# ATtiny202 register map
Vendor: Atmel; File version: 1.0
CPU: other r0p0, little endian, no MPU, no FPU, 4 interrupt priority bits
Registers are 8-bit, read-write, reset 0x0 unless marked. A register's access mark holds for its fields unless they carry their own. Offsets are from the block's base; [hi:lo] are bit positions; {n}, {i} and the like mark numbered series; 'fields as' and 'values as' point back to an identical list.

## CPU
Base 0x00800034
0x00 CCP — Configuration Change Protection
  [7:0] CCP — CCP signature
    157=SPM (SPM Instruction Protection); 216=IOREG (IO Register Protection)
0x09 SPL — Stack Pointer Low
0x0A SPH — Stack Pointer High
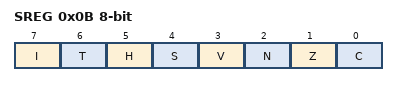
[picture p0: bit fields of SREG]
0x0B SREG — Status Register
  [7] I — Global Interrupt Enable Flag
  [6] T — Transfer Bit
  [5] H — Half Carry Flag
  [4] S — N Exclusive Or V Flag
  [3] V — Two's Complement Overflow Flag
  [2] N — Negative Flag
  [1] Z — Zero Flag
  [0] C — Carry Flag

## CPUINT — Interrupt Controller
Base 0x00800110
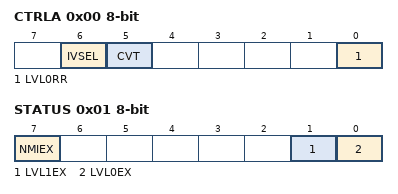
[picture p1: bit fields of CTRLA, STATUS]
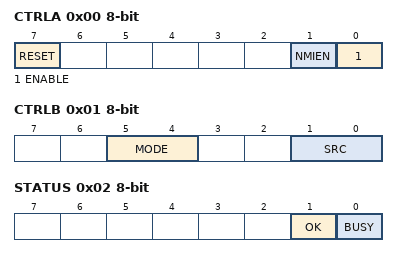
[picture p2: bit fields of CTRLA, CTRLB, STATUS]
0x00 CTRLA — Control A
  [6] IVSEL — Interrupt Vector Select
  [5] CVT — Compact Vector Table
  [0] LVL0RR — Round-robin Scheduling Enable
0x01 STATUS
  [7] NMIEX ro — Non-maskable Interrupt Executing
  [1] LVL1EX ro — Level 1 Interrupt Executing
  [0] LVL0EX ro — Level 0 Interrupt Executing
0x02 LVL0PRI — Interrupt Level 0 Priority
  [7:0] LVL0PRI — Interrupt Level Priority
0x03 LVL1VEC — Interrupt Level 1 Priority Vector
  [7:0] LVL1VEC — Interrupt Vector with High Priority

## CRCSCAN
Base 0x00800120
0x00 CTRLA — Control A
  [7] RESET — Reset CRC scan
  [1] NMIEN — Enable NMI Trigger
  [0] ENABLE — Enable CRC scan
0x01 CTRLB — Control B
  [5:4] MODE — CRC Flash Access Mode
    0=PRIORITY (Priority to flash)
  [1:0] SRC — CRC Source
    0=FLASH (CRC on entire flash); 1=APPLICATION (CRC on boot and appl section of flash); 2=BOOT (CRC on boot section of flash)
0x02 STATUS ro
  [1] OK — CRC Ok
  [0] BUSY — CRC Busy

## EVSYS — Event System
Base 0x00800180
0x00 ASYNCSTROBE wo — Asynchronous Channel Strobe
0x01 SYNCSTROBE wo — Synchronous Channel Strobe
0x02 ASYNCCH0 — Asynchronous Channel 0 Generator Selection
  [7:0] ASYNCCH0
    0=OFF; 1=CCL_LUT0 (Configurable Custom Logic LUT0); 2=CCL_LUT1 (Configurable Custom Logic LUT1); 3=AC0_OUT (Analog Comparator 0 out); 4=TCD0_CMPBCLR (Timer/Counter D0 compare B clear); 5=TCD0_CMPASET (Timer/Counter D0 compare A set); 6=TCD0_CMPBSET (Timer/Counter D0 compare B set); 7=TCD0_PROGEV (Timer/Counter D0 program event); 8=RTC_OVF (Real Time Counter overflow); 9=RTC_CMP (Real Time Counter compare); {v}=PORTA_PIN{v-10} (Asynchronous Event from Pin PA{v-10}) (v=10..17); 18=UPDI (Unified Program and debug interface)
0x03 ASYNCCH1 — Asynchronous Channel 1 Generator Selection
  [7:0] ASYNCCH1
    0=OFF; 1=CCL_LUT0 (Configurable custom logic LUT0); 2=CCL_LUT1 (Configurable custom logic LUT1); 3=AC0_OUT (Analog Comparator 0 out); 4=TCD0_CMPBCLR (Timer/Counter D0 compare B clear); 5=TCD0_CMPASET (Timer/Counter D0 compare A set); 6=TCD0_CMPBSET (Timer/Counter D0 compare B set); 7=TCD0_PROGEV (Timer/Counter D0 program event); 8=RTC_OVF (Real Time Counter overflow); 9=RTC_CMP (Real Time Counter compare); {v}=PORTB_PIN{v-10} (Asynchronous Event from Pin PB{v-10}) (v=10..17)
0x0A SYNCCH0 — Synchronous Channel 0 Generator Selection
  [7:0] SYNCCH0
    0=OFF; 1=TCB0 (Timer/Counter B0); 2=TCA0_OVF_LUNF (Timer/Counter A0 overflow); 3=TCA0_HUNF (Timer/Counter A0 underflow high byte (split mode)); 4=TCA0_CMP0 (Timer/Counter A0 compare 0); 5=TCA0_CMP1 (Timer/Counter A0 compare 1); 6=TCA0_CMP2 (Timer/Counter A0 compare 2); {v}=PORTC_PIN{v-7} (Synchronous Event from Pin PC{v-7}) (v=7..12); {v}=PORTA_PIN{v-13} (Synchronous Event from Pin PA{v-13}) (v=13..20)
0x0B SYNCCH1 — Synchronous Channel 1 Generator Selection
  [7:0] SYNCCH1
    0=OFF; 1=TCB0 (Timer/Counter B0); 2=TCA0_OVF_LUNF (Timer/Counter A0 overflow); 3=TCA0_HUNF (Timer/Counter A0 underflow high byte (split mode)); 4=TCA0_CMP0 (Timer/Counter A0 compare 0); 5=TCA0_CMP1 (Timer/Counter A0 compare 1); 6=TCA0_CMP2 (Timer/Counter A0 compare 2); {v}=PORTB_PIN{v-8} (Synchronous Event from Pin PB{v-8}) (v=8..15)
0x12 ASYNCUSER0 — Asynchronous User Ch 0 Input Selection - TCB0
  [7:0] ASYNCUSER0
    0=OFF; 1=SYNCCH0 (Synchronous Event Channel 0); 3=ASYNCCH0 (Asynchronous Event Channel 0); 4=ASYNCCH1 (Asynchronous Event Channel 1)
0x13 ASYNCUSER1 — Asynchronous User Ch 1 Input Selection - ADC0
  [7:0] ASYNCUSER1
    values as ASYNCUSER0.ASYNCUSER0
0x14 ASYNCUSER2 — Asynchronous User Ch 2 Input Selection - CCL LUT0 Event 0
  [7:0] ASYNCUSER2
    values as ASYNCUSER0.ASYNCUSER0
0x15 ASYNCUSER3 — Asynchronous User Ch 3 Input Selection - CCL LUT1 Event 0
  [7:0] ASYNCUSER3
    values as ASYNCUSER0.ASYNCUSER0
0x16 ASYNCUSER4 — Asynchronous User Ch 4 Input Selection - CCL LUT0 Event 1
  [7:0] ASYNCUSER4
    values as ASYNCUSER0.ASYNCUSER0
0x17 ASYNCUSER5 — Asynchronous User Ch 5 Input Selection - CCL LUT1 Event 1
  [7:0] ASYNCUSER5
    values as ASYNCUSER0.ASYNCUSER0
0x18 ASYNCUSER6 — Asynchronous User Ch 6 Input Selection - TCD0 Event 0
  [7:0] ASYNCUSER6
    values as ASYNCUSER0.ASYNCUSER0
0x19 ASYNCUSER7 — Asynchronous User Ch 7 Input Selection - TCD0 Event 1
  [7:0] ASYNCUSER7
    values as ASYNCUSER0.ASYNCUSER0
{0x12+i} ASYNCUSER{i} (i=8..10) — Asynchronous User Ch {i} Input Selection - Event Out {i-8}
  [7:0] ASYNCUSER{i}
    values as ASYNCUSER0.ASYNCUSER0
0x22 SYNCUSER0 — Synchronous User Ch 0 Input Selection - TCA0
  [7:0] SYNCUSER0
    0=OFF; 1=SYNCCH0 (Synchronous Event Channel 0)
